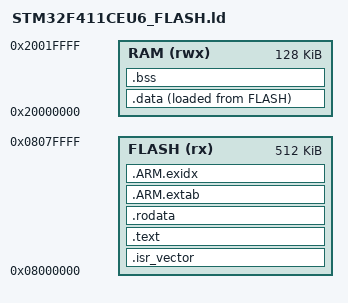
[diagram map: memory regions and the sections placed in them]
/*
 * STM32F411CEU6_FLASH.ld - 512 KB flash, 128 KB RAM, per the cover page
 * of DocID026289 Rev 4 (the E suffix in F411CE is the 512 KB density).
 */
MEMORY
{
  FLASH (rx)  : ORIGIN = 0x08000000, LENGTH = 512K
  RAM (rwx)   : ORIGIN = 0x20000000, LENGTH = 128K
}

_estack = ORIGIN(RAM) + LENGTH(RAM);

SECTIONS
{
  .isr_vector :
  {
    . = ALIGN(4);
    KEEP(*(.isr_vector))
    . = ALIGN(4);
  } >FLASH

  .text :
  {
    . = ALIGN(4);
    *(.text)
    *(.text*)
    . = ALIGN(4);
  } >FLASH

  .rodata :
  {
    . = ALIGN(4);
    *(.rodata)
    *(.rodata*)
    . = ALIGN(4);
  } >FLASH

  /* Unwind tables. Nothing here throws, but the compiler emits these for
   * C code and an unplaced section becomes an orphan the linker warns
   * about. Naming them keeps the build output silent, which matters
   * because the gate's criterion is a clean exit with no output. */
  .ARM.extab :
  {
    *(.ARM.extab* .gnu.linkonce.armextab.*)
  } >FLASH

  .ARM.exidx :
  {
    __exidx_start = .;
    *(.ARM.exidx* .gnu.linkonce.armexidx.*)
    __exidx_end = .;
  } >FLASH

  _sidata = LOADADDR(.data);

  .data :
  {
    . = ALIGN(4);
    _sdata = .;
    *(.data)
    *(.data*)
    . = ALIGN(4);
    _edata = .;
  } >RAM AT> FLASH

  .bss :
  {
    . = ALIGN(4);
    _sbss = .;
    *(.bss)
    *(.bss*)
    *(COMMON)
    . = ALIGN(4);
    _ebss = .;
  } >RAM
}
